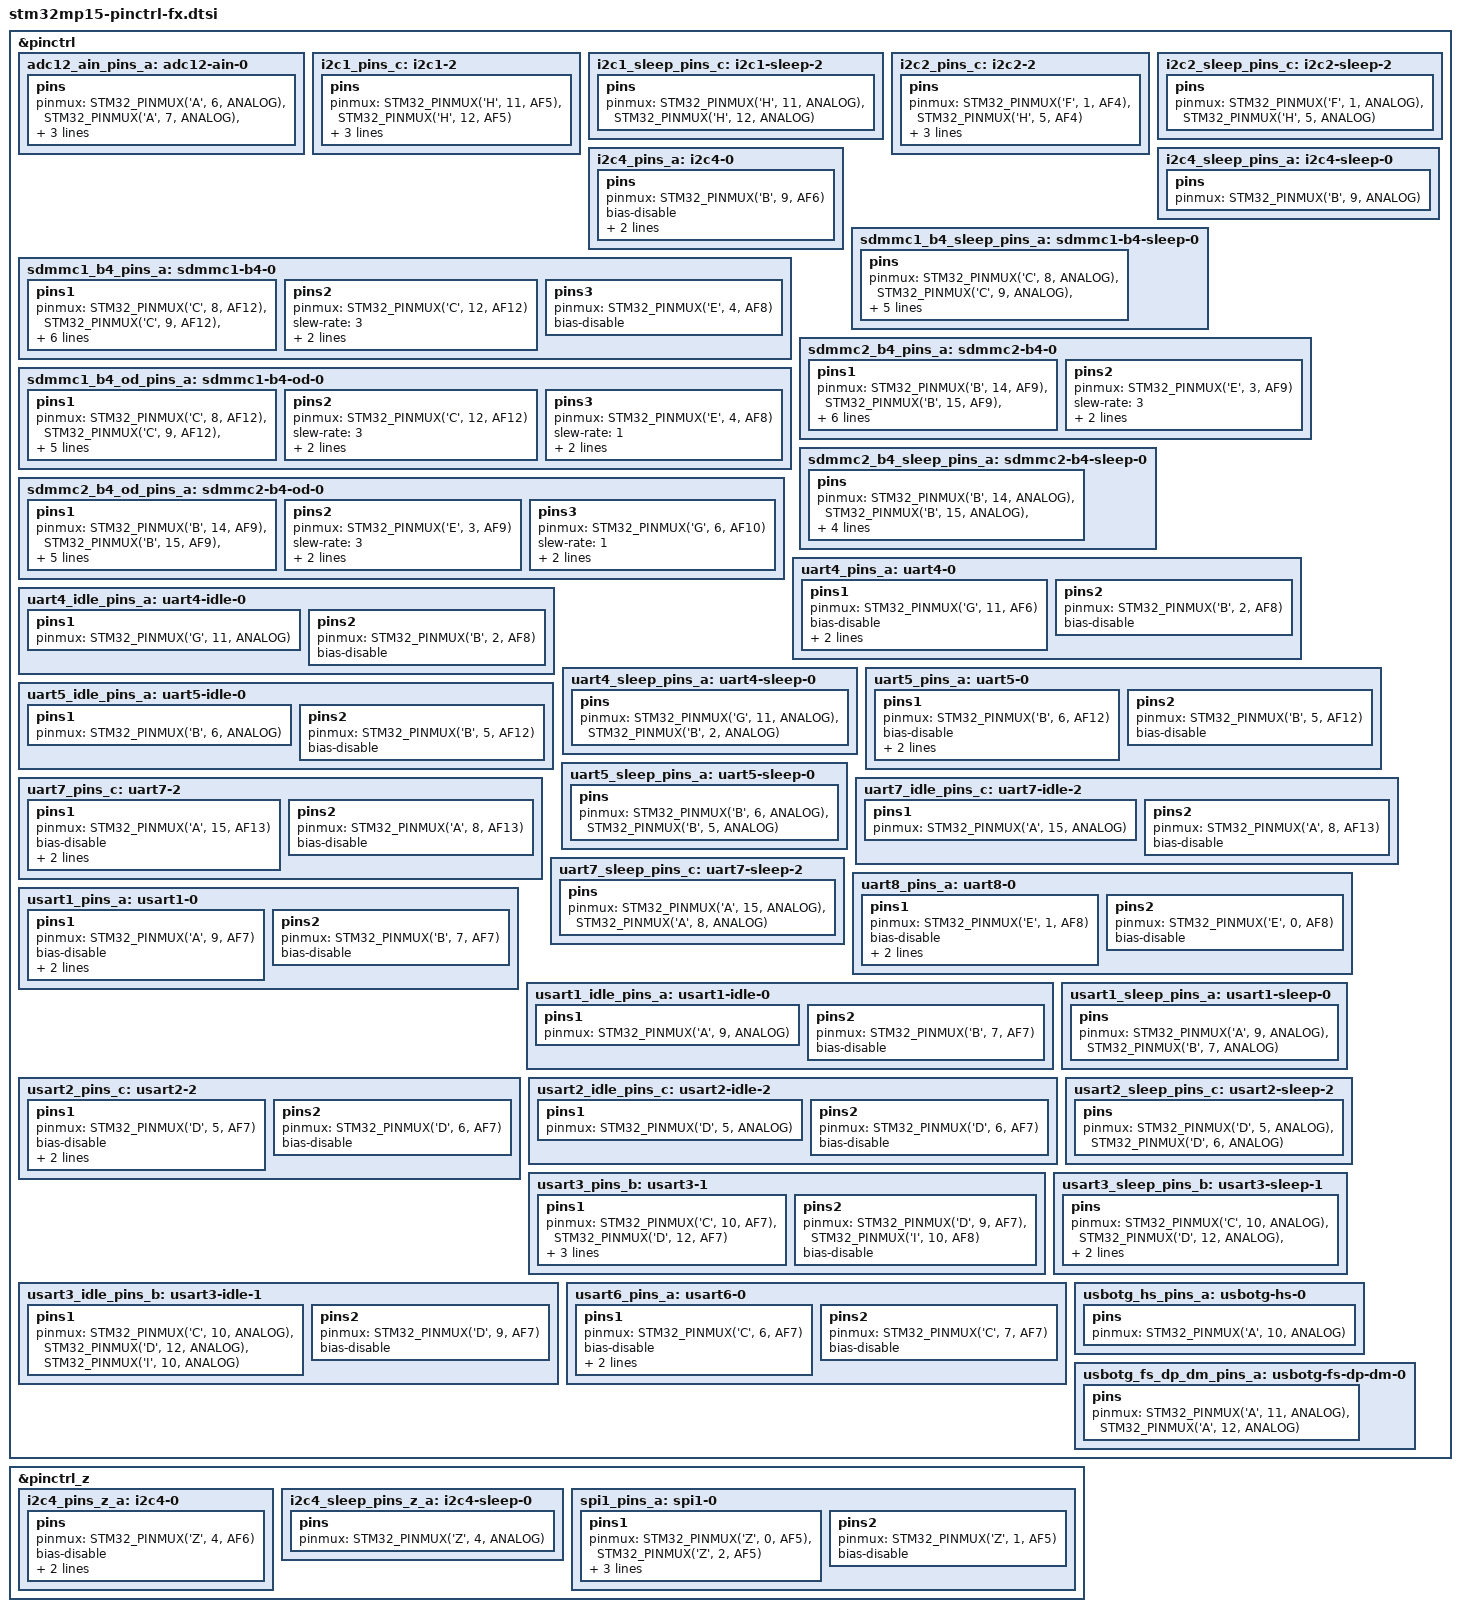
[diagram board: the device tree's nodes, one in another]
// SPDX-License-Identifier: (GPL-2.0+ OR BSD-3-Clause)
/*
 * Copyright (C) STMicroelectronics 2017 - All Rights Reserved
 * Author: Ludovic Barre <ludovic.barre@st.com> for STMicroelectronics.
 */
#include <dt-bindings/pinctrl/stm32-pinfunc.h>

&pinctrl {
	adc12_ain_pins_a: adc12-ain-0 {
		pins {
			pinmux = <STM32_PINMUX('A', 6, ANALOG)>, /* ADC1_INP3 */
				 <STM32_PINMUX('A', 7, ANALOG)>, /* ADC1_INP7 */
				 <STM32_PINMUX('B', 1, ANALOG)>, /* ADC1_INP5 */
				 <STM32_PINMUX('C', 4, ANALOG)>, /* ADC1_INP4 */
				 <STM32_PINMUX('F', 12, ANALOG)>; /* ADC1_INP6 */
		};
	};

	i2c1_pins_c: i2c1-2 {
		pins {
			pinmux = <STM32_PINMUX('H', 11, AF5)>, /* I2C1_SCL */
				 <STM32_PINMUX('H', 12, AF5)>; /* I2C1_SDA */
			bias-disable;
			drive-open-drain;
			slew-rate = <0>;
		};
	};

	i2c1_sleep_pins_c: i2c1-sleep-2 {
		pins {
			pinmux = <STM32_PINMUX('H', 11, ANALOG)>, /* I2C1_SCL */
				 <STM32_PINMUX('H', 12, ANALOG)>; /* I2C1_SDA */
		};
	};

	i2c2_pins_c: i2c2-2 {
		pins {
			pinmux = <STM32_PINMUX('F', 1, AF4)>, /* I2C2_SCL */
				 <STM32_PINMUX('H', 5, AF4)>; /* I2C2_SDA */
			bias-disable;
			drive-open-drain;
			slew-rate = <0>;
		};
	};

	i2c2_sleep_pins_c: i2c2-sleep-2 {
		pins {
			pinmux = <STM32_PINMUX('F', 1, ANALOG)>, /* I2C2_SCL */
				 <STM32_PINMUX('H', 5, ANALOG)>; /* I2C2_SDA */
		};
	};
	
	i2c4_pins_a: i2c4-0 {
		pins {
			pinmux = <STM32_PINMUX('B', 9, AF6)>; /* I2C4_SDA */			
			bias-disable;
			drive-open-drain;
			slew-rate = <0>;
		};
	};

	i2c4_sleep_pins_a: i2c4-sleep-0 {
		pins {
			pinmux = <STM32_PINMUX('B', 9, ANALOG)>; /* I2C4_SDA */
		};
	};

	sdmmc1_b4_pins_a: sdmmc1-b4-0 {
		pins1 {
			pinmux = <STM32_PINMUX('C', 8, AF12)>, /* SDMMC1_D0 */
				 <STM32_PINMUX('C', 9, AF12)>, /* SDMMC1_D1 */
				 <STM32_PINMUX('E', 6, AF8)>, /* SDMMC1_D2 */
				 <STM32_PINMUX('C', 11, AF12)>, /* SDMMC1_D3 */
				 <STM32_PINMUX('D', 2, AF12)>; /* SDMMC1_CMD */
			slew-rate = <1>;
			drive-push-pull;
			bias-disable;
		};
		pins2 {
			pinmux = <STM32_PINMUX('C', 12, AF12)>; /* SDMMC1_CK */
			slew-rate = <3>;
			drive-push-pull;
			bias-disable;
		};
		pins3 {
			pinmux = <STM32_PINMUX('E', 4, AF8)>; /* SDMMC1_CKIN */
			bias-disable;
		};
	};

	sdmmc1_b4_od_pins_a: sdmmc1-b4-od-0 {
		pins1 {
			pinmux = <STM32_PINMUX('C', 8, AF12)>, /* SDMMC1_D0 */
				 <STM32_PINMUX('C', 9, AF12)>, /* SDMMC1_D1 */
				 <STM32_PINMUX('E', 6, AF8)>, /* SDMMC1_D2 */
				 <STM32_PINMUX('C', 11, AF12)>; /* SDMMC1_D3 */
			slew-rate = <1>;
			drive-push-pull;
			bias-disable;
		};
		pins2 {
			pinmux = <STM32_PINMUX('C', 12, AF12)>; /* SDMMC1_CK */
			slew-rate = <3>;
			drive-push-pull;
			bias-disable;
		};
		pins3 {
			pinmux = <STM32_PINMUX('D', 2, AF12)>; /* SDMMC1_CMD */
			slew-rate = <1>;
			drive-open-drain;
			bias-disable;
		};
		pins3 {
			pinmux = <STM32_PINMUX('E', 4, AF8)>; /* SDMMC1_CKIN */
			bias-disable;
		};
	};

	sdmmc1_b4_sleep_pins_a: sdmmc1-b4-sleep-0 {
		pins {
			pinmux = <STM32_PINMUX('C', 8, ANALOG)>, /* SDMMC1_D0 */
				 <STM32_PINMUX('C', 9, ANALOG)>, /* SDMMC1_D1 */
				 <STM32_PINMUX('E', 6, ANALOG)>, /* SDMMC1_D2 */
				 <STM32_PINMUX('C', 11, ANALOG)>, /* SDMMC1_D3 */
				 <STM32_PINMUX('C', 12, ANALOG)>, /* SDMMC1_CK */
				 <STM32_PINMUX('D', 2, ANALOG)>; /* SDMMC1_CMD */
				 <STM32_PINMUX('E', 4, ANALOG)>; /* SDMMC1_CKIN */
		};
	};

	sdmmc2_b4_pins_a: sdmmc2-b4-0 {
		pins1 {
			pinmux = <STM32_PINMUX('B', 14, AF9)>, /* SDMMC2_D0 */
				 <STM32_PINMUX('B', 15, AF9)>, /* SDMMC2_D1 */
				 <STM32_PINMUX('B', 3, AF9)>, /* SDMMC2_D2 */
				 <STM32_PINMUX('B', 4, AF9)>, /* SDMMC2_D3 */
				 <STM32_PINMUX('G', 6, AF10)>; /* SDMMC2_CMD */
			slew-rate = <1>;
			drive-push-pull;
			bias-pull-up;
		};
		pins2 {
			pinmux = <STM32_PINMUX('E', 3, AF9)>; /* SDMMC2_CK */
			slew-rate = <3>;
			drive-push-pull;
			bias-pull-up;
		};
	};

	sdmmc2_b4_od_pins_a: sdmmc2-b4-od-0 {
		pins1 {
			pinmux = <STM32_PINMUX('B', 14, AF9)>, /* SDMMC2_D0 */
				 <STM32_PINMUX('B', 15, AF9)>, /* SDMMC2_D1 */
				 <STM32_PINMUX('B', 3, AF9)>, /* SDMMC2_D2 */
				 <STM32_PINMUX('B', 4, AF9)>; /* SDMMC2_D3 */
			slew-rate = <1>;
			drive-push-pull;
			bias-pull-up;
		};
		pins2 {
			pinmux = <STM32_PINMUX('E', 3, AF9)>; /* SDMMC2_CK */
			slew-rate = <3>;
			drive-push-pull;
			bias-pull-up;
		};
		pins3 {
			pinmux = <STM32_PINMUX('G', 6, AF10)>; /* SDMMC2_CMD */
			slew-rate = <1>;
			drive-open-drain;
			bias-pull-up;
		};
	};

	sdmmc2_b4_sleep_pins_a: sdmmc2-b4-sleep-0 {
		pins {
			pinmux = <STM32_PINMUX('B', 14, ANALOG)>, /* SDMMC2_D0 */
				 <STM32_PINMUX('B', 15, ANALOG)>, /* SDMMC2_D1 */
				 <STM32_PINMUX('B', 3, ANALOG)>, /* SDMMC2_D2 */
				 <STM32_PINMUX('B', 4, ANALOG)>, /* SDMMC2_D3 */
				 <STM32_PINMUX('E', 3, ANALOG)>, /* SDMMC2_CK */
				 <STM32_PINMUX('G', 6, ANALOG)>; /* SDMMC2_CMD */
		};
	};

	uart4_pins_a: uart4-0 {
		pins1 {
			pinmux = <STM32_PINMUX('G', 11, AF6)>; /* UART4_TX */
			bias-disable;
			drive-push-pull;
			slew-rate = <0>;
		};
		pins2 {
			pinmux = <STM32_PINMUX('B', 2, AF8)>; /* UART4_RX */
			bias-disable;
		};
	};

	uart4_idle_pins_a: uart4-idle-0 {
		   pins1 {
			 pinmux = <STM32_PINMUX('G', 11, ANALOG)>; /* UART4_TX */
		   };
		   pins2 {
			 pinmux = <STM32_PINMUX('B', 2, AF8)>; /* UART4_RX */
			 bias-disable;
		   };
	};

	uart4_sleep_pins_a: uart4-sleep-0 {
		   pins {
			pinmux = <STM32_PINMUX('G', 11, ANALOG)>, /* UART4_TX */
				 <STM32_PINMUX('B', 2, ANALOG)>; /* UART4_RX */
		    };
	};

	uart5_pins_a: uart5-0 {
		pins1 {
			pinmux = <STM32_PINMUX('B', 6, AF12)>; /* UART5_TX */
			bias-disable;
			drive-push-pull;
			slew-rate = <0>;
		};
		pins2 {
			pinmux = <STM32_PINMUX('B', 5, AF12)>; /* UART5_RX */
			bias-disable;
		};
	};

	uart5_idle_pins_a: uart5-idle-0 {
		pins1 {
			pinmux = <STM32_PINMUX('B', 6, ANALOG)>; /* UART5_TX */
		};
		pins2 {
			pinmux = <STM32_PINMUX('B', 5, AF12)>; /* UART5_RX */
			bias-disable;
		};
	};

	uart5_sleep_pins_a: uart5-sleep-0 {
		pins {
			pinmux = <STM32_PINMUX('B', 6, ANALOG)>, /* UART5_TX */
				<STM32_PINMUX('B', 5, ANALOG)>; /* UART5_RX */
		};
	};

	uart7_pins_c: uart7-2 {
		pins1 {
			pinmux = <STM32_PINMUX('A', 15, AF13)>; /* UART7_TX */
			bias-disable;
			drive-push-pull;
			slew-rate = <0>;
		};
		pins2 {
			pinmux = <STM32_PINMUX('A', 8, AF13)>; /* UART7_RX */
			bias-disable;
		};
	};

	uart7_idle_pins_c: uart7-idle-2 {
		pins1 {
			pinmux = <STM32_PINMUX('A', 15, ANALOG)>; /* UART7_TX */
		};
		pins2 {
			pinmux = <STM32_PINMUX('A', 8, AF13)>; /* UART7_RX */
			bias-disable;
		};
	};

	uart7_sleep_pins_c: uart7-sleep-2 {
		pins {
			pinmux = <STM32_PINMUX('A', 15, ANALOG)>, /* UART7_TX */
				 <STM32_PINMUX('A', 8, ANALOG)>; /* UART7_RX */
		};
	};

	uart8_pins_a: uart8-0 {
		pins1 {
			pinmux = <STM32_PINMUX('E', 1, AF8)>; /* UART8_TX */
			bias-disable;
			drive-push-pull;
			slew-rate = <0>;
		};
		pins2 {
			pinmux = <STM32_PINMUX('E', 0, AF8)>; /* UART8_RX */
			bias-disable;
		};
	};

	usart1_pins_a: usart1-0 {
		pins1 {
			pinmux = <STM32_PINMUX('A', 9, AF7)>; /* USART1_TX */
			bias-disable;
			drive-push-pull;
			slew-rate = <0>;
		};
		pins2 {
			pinmux = <STM32_PINMUX('B', 7, AF7)>; /* USART1_RX */
			bias-disable;
		};
	};

	usart1_idle_pins_a: usart1-idle-0 {
		pins1 {
			pinmux = <STM32_PINMUX('A', 9, ANALOG)>; /* USART1_TX */
		};
		pins2 {
			pinmux = <STM32_PINMUX('B', 7, AF7)>; /* USART1_RX */
			bias-disable;
		};
	};

	usart1_sleep_pins_a: usart1-sleep-0 {
		pins {
			pinmux = <STM32_PINMUX('A', 9, ANALOG)>, /* USART1_TX */
				<STM32_PINMUX('B', 7, ANALOG)>; /* USART1_RX */
		};
	};

	usart2_pins_c: usart2-2 {
		pins1 {
			pinmux = <STM32_PINMUX('D', 5, AF7)>; /* USART2_TX */
			bias-disable;
			drive-push-pull;
			slew-rate = <0>;
		};
		pins2 {
			pinmux = <STM32_PINMUX('D', 6, AF7)>; /* USART2_RX */
			bias-disable;
		};
	};

	usart2_idle_pins_c: usart2-idle-2 {
		pins1 {
			pinmux = <STM32_PINMUX('D', 5, ANALOG)>; /* USART2_TX */
		};
		pins2 {
			pinmux = <STM32_PINMUX('D', 6, AF7)>; /* USART2_RX */
			bias-disable;
		};
	};

	usart2_sleep_pins_c: usart2-sleep-2 {
		pins {
			pinmux = <STM32_PINMUX('D', 5, ANALOG)>, /* USART2_TX */
				 <STM32_PINMUX('D', 6, ANALOG)>; /* USART2_RX */
		};
	};

	usart3_pins_b: usart3-1 {
		pins1 {
			pinmux = <STM32_PINMUX('C', 10, AF7)>, /* USART3_TX */
				 <STM32_PINMUX('D', 12, AF7)>; /* USART3_RTS */
			bias-disable;
			drive-push-pull;
			slew-rate = <0>;
		};
		pins2 {
			pinmux = <STM32_PINMUX('D', 9, AF7)>, /* USART3_RX */
				 <STM32_PINMUX('I', 10, AF8)>; /* USART3_CTS_NSS */
			bias-disable;
		};
	};

	usart3_idle_pins_b: usart3-idle-1 {
		pins1 {
			pinmux = <STM32_PINMUX('C', 10, ANALOG)>, /* USART3_TX */
				 <STM32_PINMUX('D', 12, ANALOG)>, /* USART3_RTS */
				 <STM32_PINMUX('I', 10, ANALOG)>; /* USART3_CTS_NSS */
		};
		pins2 {
			pinmux = <STM32_PINMUX('D', 9, AF7)>; /* USART3_RX */
			bias-disable;
		};
	};

	usart3_sleep_pins_b: usart3-sleep-1 {
		pins {
			pinmux = <STM32_PINMUX('C', 10, ANALOG)>, /* USART3_TX */
				 <STM32_PINMUX('D', 12, ANALOG)>, /* USART3_RTS */
				 <STM32_PINMUX('I', 10, ANALOG)>, /* USART3_CTS_NSS */
				 <STM32_PINMUX('D', 9, ANALOG)>; /* USART3_RX */
		};
	};

	usart6_pins_a: usart6-0 {
		pins1 {
			pinmux = <STM32_PINMUX('C', 6, AF7)>; /* USART6_TX */
			bias-disable;
			drive-push-pull;
			slew-rate = <0>;
		};
		pins2 {
			pinmux = <STM32_PINMUX('C', 7, AF7)>; /* USART6_RX */
			bias-disable;
		};
	};

	usbotg_hs_pins_a: usbotg-hs-0 {
		pins {
			pinmux = <STM32_PINMUX('A', 10, ANALOG)>; /* OTG_ID */
		};
	};

	usbotg_fs_dp_dm_pins_a: usbotg-fs-dp-dm-0 {
		pins {
			pinmux = <STM32_PINMUX('A', 11, ANALOG)>, /* OTG_FS_DM */
				 <STM32_PINMUX('A', 12, ANALOG)>; /* OTG_FS_DP */
		};
	};
};

&pinctrl_z {
	i2c4_pins_z_a: i2c4-0 {
		pins {
			pinmux = <STM32_PINMUX('Z', 4, AF6)>; /* I2C4_SCL */			
			bias-disable;
			drive-open-drain;
			slew-rate = <0>;
		};
	};

	i2c4_sleep_pins_z_a: i2c4-sleep-0 {
		pins {
			pinmux = <STM32_PINMUX('Z', 4, ANALOG)>; /* I2C4_SCL */
		};
	};

	spi1_pins_a: spi1-0 {
		pins1 {
			pinmux = <STM32_PINMUX('Z', 0, AF5)>, /* SPI1_SCK */
				 <STM32_PINMUX('Z', 2, AF5)>; /* SPI1_MOSI */
			bias-disable;
			drive-push-pull;
			slew-rate = <1>;
		};
		pins2 {
			pinmux = <STM32_PINMUX('Z', 1, AF5)>; /* SPI1_MISO */
			bias-disable;
		};
	};
};
